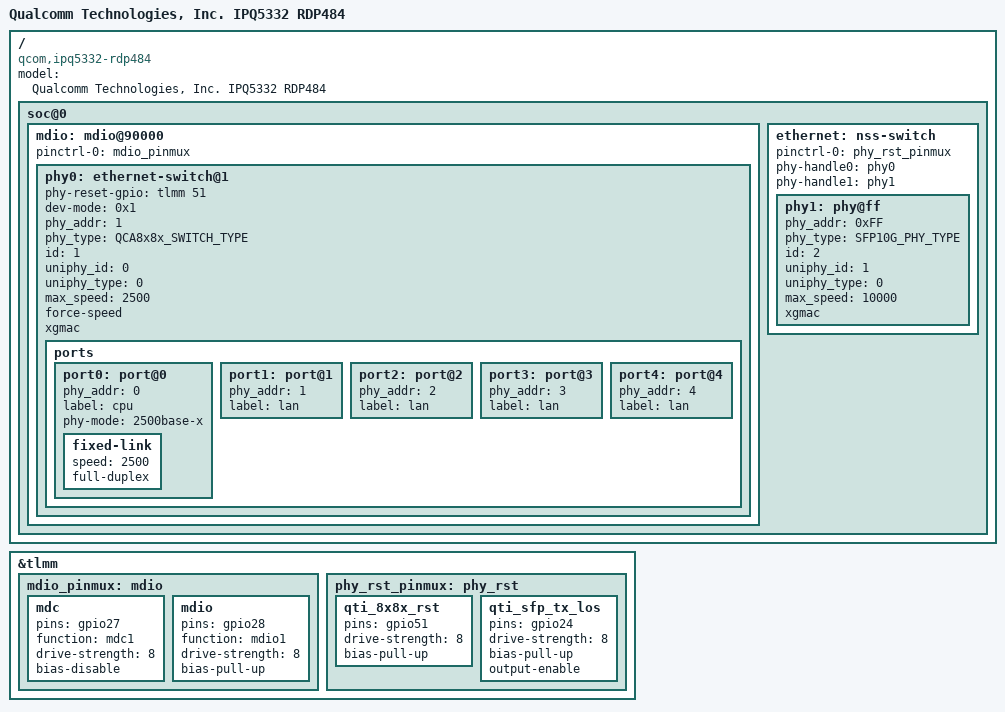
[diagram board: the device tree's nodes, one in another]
// SPDX-License-Identifier: GPL-2.0-only
/*
 * Copyright (c) Qualcomm Technologies, Inc. and/or its subsidiaries.
 */

/dts-v1/;

#include "ipq5332-rdp-common.dtsi"

/ {
	model = "Qualcomm Technologies, Inc. IPQ5332 RDP484";
	compatible = "qcom,ipq5332-rdp484", "qcom,ipq5332";

	soc@0 {
		mdio: mdio@90000 {
			pinctrl-names = "default";
			pinctrl-0 = <&mdio_pinmux>;
			status = "okay";

			phy0: ethernet-switch@1 {
				phy-reset-gpio = <&tlmm 51 0>;
				dev-mode = <0x1>;
				phy_addr = <1>;
				phy_type = <QCA8x8x_SWITCH_TYPE>;
				id = <1>;
				uniphy_id = <0>;
				uniphy_type = <0>;
				max_speed = <2500>;
				force-speed;
				xgmac;
				ports {
					#address-cells = <1>;
					#size-cells = <0>;

					port0: port@0 {
						phy_addr = <0>;
						label = "cpu";
						phy-mode = "2500base-x";
						fixed-link {
							speed = <2500>;
							full-duplex;
						};
					};

					port1: port@1 {
						phy_addr = <1>;
						label = "lan";
					};

					port2: port@2 {
						phy_addr = <2>;
						label = "lan";
					};

					port3: port@3 {
						phy_addr = <3>;
						label = "lan";
					};

					port4: port@4 {
						phy_addr = <4>;
						label = "lan";
					};
				};
			};
		};

		ethernet: nss-switch {
			pinctrl-names = "default";
			pinctrl-0 = <&phy_rst_pinmux>;
			phy-handle0 = <&phy0>;
			phy-handle1 = <&phy1>;
			status = "okay";

			phy1: phy@ff {
				phy_addr = <0xFF>;
				phy_type = <SFP10G_PHY_TYPE>;
				id = <2>;
				uniphy_id = <1>;
				uniphy_type = <0>;
				max_speed = <10000>;
				xgmac;
			};
		};
	};
};

&tlmm {
	mdio_pinmux: mdio {
		mdc {
			pins = "gpio27";
			function = "mdc1";
			drive-strength = <8>;
			bias-disable;
		};

		mdio {
			pins = "gpio28";
			function = "mdio1";
			drive-strength = <8>;
			bias-pull-up;
		};
	};

	phy_rst_pinmux: phy_rst {
		qti_8x8x_rst {
			pins = "gpio51";
			drive-strength = <8>;
			bias-pull-up;
		};

		qti_sfp_tx_los {
			pins = "gpio24";
			drive-strength = <8>;
			bias-pull-up;
			output-enable;
		};
	};
};
